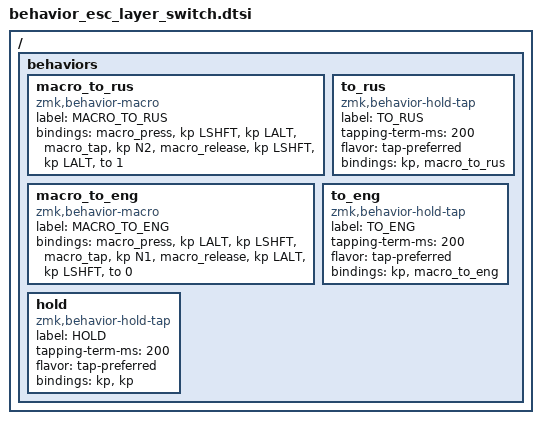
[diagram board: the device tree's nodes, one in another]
/ {
  behaviors {
    macro_to_rus: macro_to_rus {
      compatible = "zmk,behavior-macro";
      label = "MACRO_TO_RUS";
      #binding-cells = <0>;
      bindings = < &macro_press &kp LSHFT &kp LALT >
               , < &macro_tap &kp N2 >
               , < &macro_release &kp LSHFT &kp LALT >
               , < &to 1 >;
    };

    macro_to_eng: macro_to_eng {
      compatible = "zmk,behavior-macro";
      label = "MACRO_TO_ENG";
      #binding-cells = <0>;
      bindings = < &macro_press &kp LALT &kp LSHFT >
               , < &macro_tap &kp N1 >
               , < &macro_release &kp LALT &kp LSHFT >
               , < &to 0 >;
    };

    to_rus: to_rus {
      compatible = "zmk,behavior-hold-tap";
      label = "TO_RUS";
      #binding-cells = <2>;
      tapping-term-ms = <200>;
      flavor = "tap-preferred";
      bindings = <&kp>, <&macro_to_rus>;
    };

    to_eng: to_eng {
      compatible = "zmk,behavior-hold-tap";
      label = "TO_ENG";
      #binding-cells = <2>;
      tapping-term-ms = <200>;
      flavor = "tap-preferred";
      bindings = <&kp>, <&macro_to_eng>;
    };

    hold: hold {
      compatible = "zmk,behavior-hold-tap";
      label = "HOLD";
      #binding-cells = <2>;
      tapping-term-ms = <200>;
      flavor = "tap-preferred";
      bindings = <&kp>, <&kp>;
    };
  };
};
